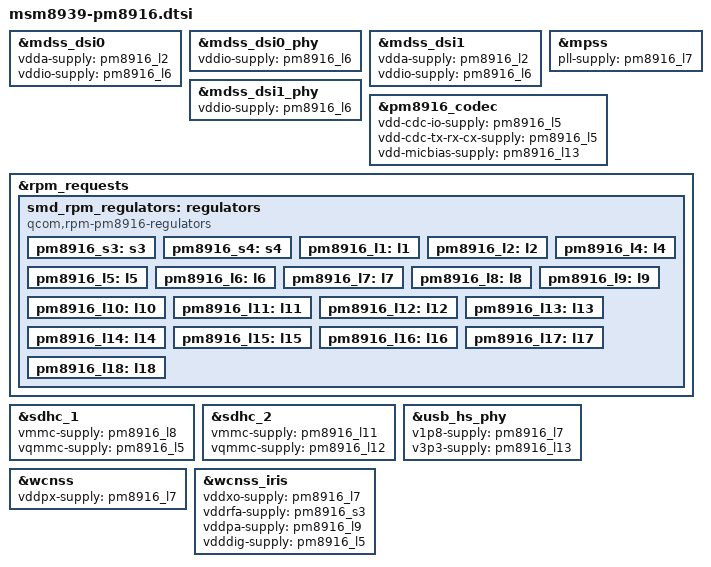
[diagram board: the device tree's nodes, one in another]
// SPDX-License-Identifier: GPL-2.0-only
/*
 * msm8939-pm8916.dtsi describes common properties (e.g. regulator connections)
 * that apply to most devices that make use of the MSM8939 SoC and PM8916 PMIC.
 * Many regulators have a fixed purpose in the original reference design and
 * were rarely re-used for different purposes. Devices that deviate from the
 * typical reference design should not make use of this include and instead add
 * the necessary properties in the board-specific device tree.
 */

#include "msm8939.dtsi"
#include "pm8916.dtsi"

&mdss_dsi0 {
	vdda-supply = <&pm8916_l2>;
	vddio-supply = <&pm8916_l6>;
};

&mdss_dsi0_phy {
	vddio-supply = <&pm8916_l6>;
};

&mdss_dsi1 {
	vdda-supply = <&pm8916_l2>;
	vddio-supply = <&pm8916_l6>;
};

&mdss_dsi1_phy {
	vddio-supply = <&pm8916_l6>;
};

&mpss {
	pll-supply = <&pm8916_l7>;
};

&pm8916_codec {
	vdd-cdc-io-supply = <&pm8916_l5>;
	vdd-cdc-tx-rx-cx-supply = <&pm8916_l5>;
	vdd-micbias-supply = <&pm8916_l13>;
};

&rpm_requests {
	smd_rpm_regulators: regulators {
		compatible = "qcom,rpm-pm8916-regulators";

		/* pm8916_s1 is managed by rpmpd (MSM8939_VDDMDCX) */
		/* pm8916_s2 is managed by rpmpd (MSM8939_VDDCX) */
		pm8916_s3: s3 {};
		pm8916_s4: s4 {};

		pm8916_l1: l1 {};
		pm8916_l2: l2 {};
		/* pm8916_l3 is managed by rpmpd (MSM8939_VDDMX) */
		pm8916_l4: l4 {};
		pm8916_l5: l5 {};
		pm8916_l6: l6 {};
		pm8916_l7: l7 {};
		pm8916_l8: l8 {};
		pm8916_l9: l9 {};
		pm8916_l10: l10 {};
		pm8916_l11: l11 {};
		pm8916_l12: l12 {};
		pm8916_l13: l13 {};
		pm8916_l14: l14 {};
		pm8916_l15: l15 {};
		pm8916_l16: l16 {};
		pm8916_l17: l17 {};
		pm8916_l18: l18 {};
	};
};

&sdhc_1 {
	vmmc-supply = <&pm8916_l8>;
	vqmmc-supply = <&pm8916_l5>;
};

&sdhc_2 {
	vmmc-supply = <&pm8916_l11>;
	vqmmc-supply = <&pm8916_l12>;
};

&usb_hs_phy {
	v1p8-supply = <&pm8916_l7>;
	v3p3-supply = <&pm8916_l13>;
};

&wcnss {
	vddpx-supply = <&pm8916_l7>;
};

&wcnss_iris {
	vddxo-supply = <&pm8916_l7>;
	vddrfa-supply = <&pm8916_s3>;
	vddpa-supply = <&pm8916_l9>;
	vdddig-supply = <&pm8916_l5>;
};
